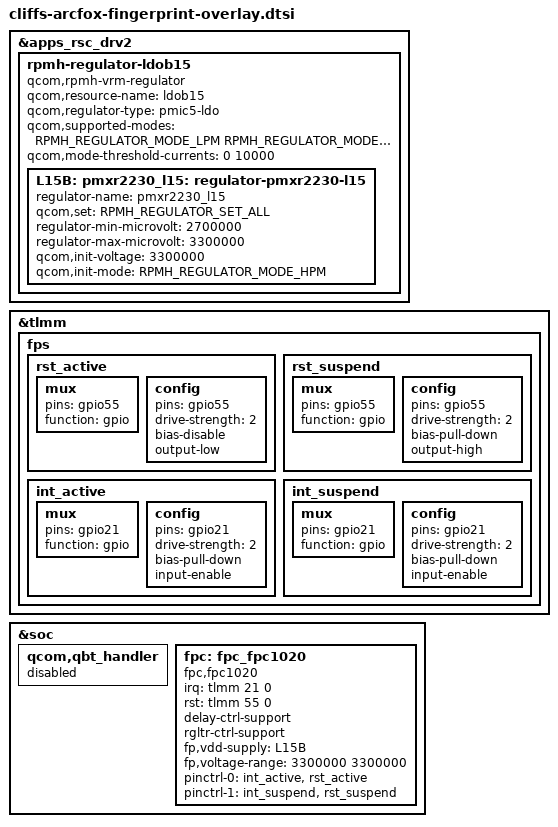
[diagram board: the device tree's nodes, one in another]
/* Copyright (c) 2021, The Linux Foundation. All rights reserved.
 *
 * This program is free software; you can redistribute it and/or modify
 * it under the terms of the GNU General Public License version 2 and
 * only version 2 as published by the Free Software Foundation.
 *
 * This program is distributed in the hope that it will be useful,
 * but WITHOUT ANY WARRANTY; without even the implied warranty of
 * MERCHANTABILITY or FITNESS FOR A PARTICULAR PURPOSE.  See the
 * GNU General Public License for more details.
 */

#include <dt-bindings/regulator/qcom,rpmh-regulator-levels.h>

&apps_rsc_drv2 {
	rpmh-regulator-ldob15 {
		compatible = "qcom,rpmh-vrm-regulator";
		qcom,resource-name = "ldob15";
		qcom,regulator-type = "pmic5-ldo";
		qcom,supported-modes =
			<RPMH_REGULATOR_MODE_LPM
			RPMH_REGULATOR_MODE_HPM>;
		qcom,mode-threshold-currents = <0 10000>;

		L15B:
		pmxr2230_l15: regulator-pmxr2230-l15 {
			regulator-name = "pmxr2230_l15";
			qcom,set = <RPMH_REGULATOR_SET_ALL>;
			regulator-min-microvolt = <2700000>;
			regulator-max-microvolt = <3300000>;
			qcom,init-voltage = <3000000>;
			qcom,init-mode = <RPMH_REGULATOR_MODE_HPM>;
		};
	};
};

&tlmm {

	fps {
		rst_active: rst_active {
			/* RESET */
			mux {
				pins = "gpio55";
				function = "gpio";
			};
			config {
				pins = "gpio55";
				drive-strength = <2>; /* 2 MA */
				bias-disable;
				output-low;
			};
		};

		rst_suspend: rst_suspend{
			/* RESET */
			mux {
				pins = "gpio55";
				function = "gpio";
			};

			config {
				pins = "gpio55";
				drive-strength = <2>; /* 2 MA */
				bias-pull-down; /* pull down */
				output-high;
			};
		};

		int_active: int_active {
			/* INTERRUPT */
			mux {
				pins = "gpio21";
				function = "gpio";
			};

			config {
				pins = "gpio21";
				drive-strength = <2>; /* 2 MA */
				bias-pull-down; /* pull down */
				input-enable;
			};
		};

		int_suspend: int_suspend{
			/* INTERRUPT */
			mux {
				pins = "gpio21";
				function = "gpio";
			};

			config {
				pins = "gpio21";
				drive-strength = <2>; /* 2 MA */
				bias-pull-down; /* pull down */
				input-enable;
			};
		};
	};
};

&L15B {
	regulator-max-microvolt = <3300000>;
	qcom,init-voltage = <3300000>;
	status = "ok";
};

&soc {
	qcom,qbt_handler {
		status = "disabled";
	};

	fpc: fpc_fpc1020 {
		compatible = "fpc,fpc1020";
		status = "ok";
		irq = <&tlmm 21 0>;
		rst = <&tlmm 55 0>;
		delay-ctrl-support;
		rgltr-ctrl-support;
		fp,vdd-supply=<&L15B>;
		fp,voltage-range = <3300000 3300000>;
		pinctrl-names = "default", "suspend";
		pinctrl-0 = <&int_active &rst_active>;
		pinctrl-1 = < &int_suspend &rst_suspend>;
	};
};
